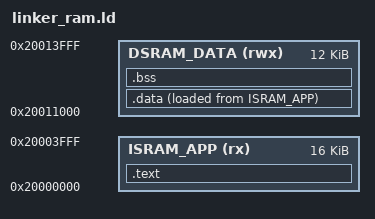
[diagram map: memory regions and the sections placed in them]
/* Generated by RISC_AXI Project Console. */
ENTRY(_start)

MEMORY
{
  ISRAM_APP (rx)   : ORIGIN = 0x20000000, LENGTH = 0x00004000
  DSRAM_DATA (rwx) : ORIGIN = 0x20011000, LENGTH = 0x00003000
}

SECTIONS
{
  /DISCARD/ :
  {
    *(.note*)
    *(.comment*)
    *(.eh_frame*)
    *(.riscv.attributes)
  }

  .text :
  {
    . = ALIGN(4);
    KEEP(*(.vectors))
    KEEP(*(.text.startup))
    *(.text*)
    *(.rodata*)
    . = ALIGN(4);
  } > ISRAM_APP

  .data :
  {
    . = ALIGN(4);
    __data_start = .;
    *(.sdata*)
    *(.data*)
    . = ALIGN(4);
    __data_end = .;
  } > DSRAM_DATA AT > ISRAM_APP

  __data_load_start = LOADADDR(.data);

  .bss (NOLOAD) :
  {
    . = ALIGN(4);
    __bss_start = .;
    *(.sbss*)
    *(.bss*)
    *(COMMON)
    . = ALIGN(4);
    __bss_end = .;
  } > DSRAM_DATA

  PROVIDE(__global_pointer$ = __data_start + 0x800);

  . = ORIGIN(DSRAM_DATA) + LENGTH(DSRAM_DATA);
  . = ALIGN(16);
  __stack_top = .;
}
